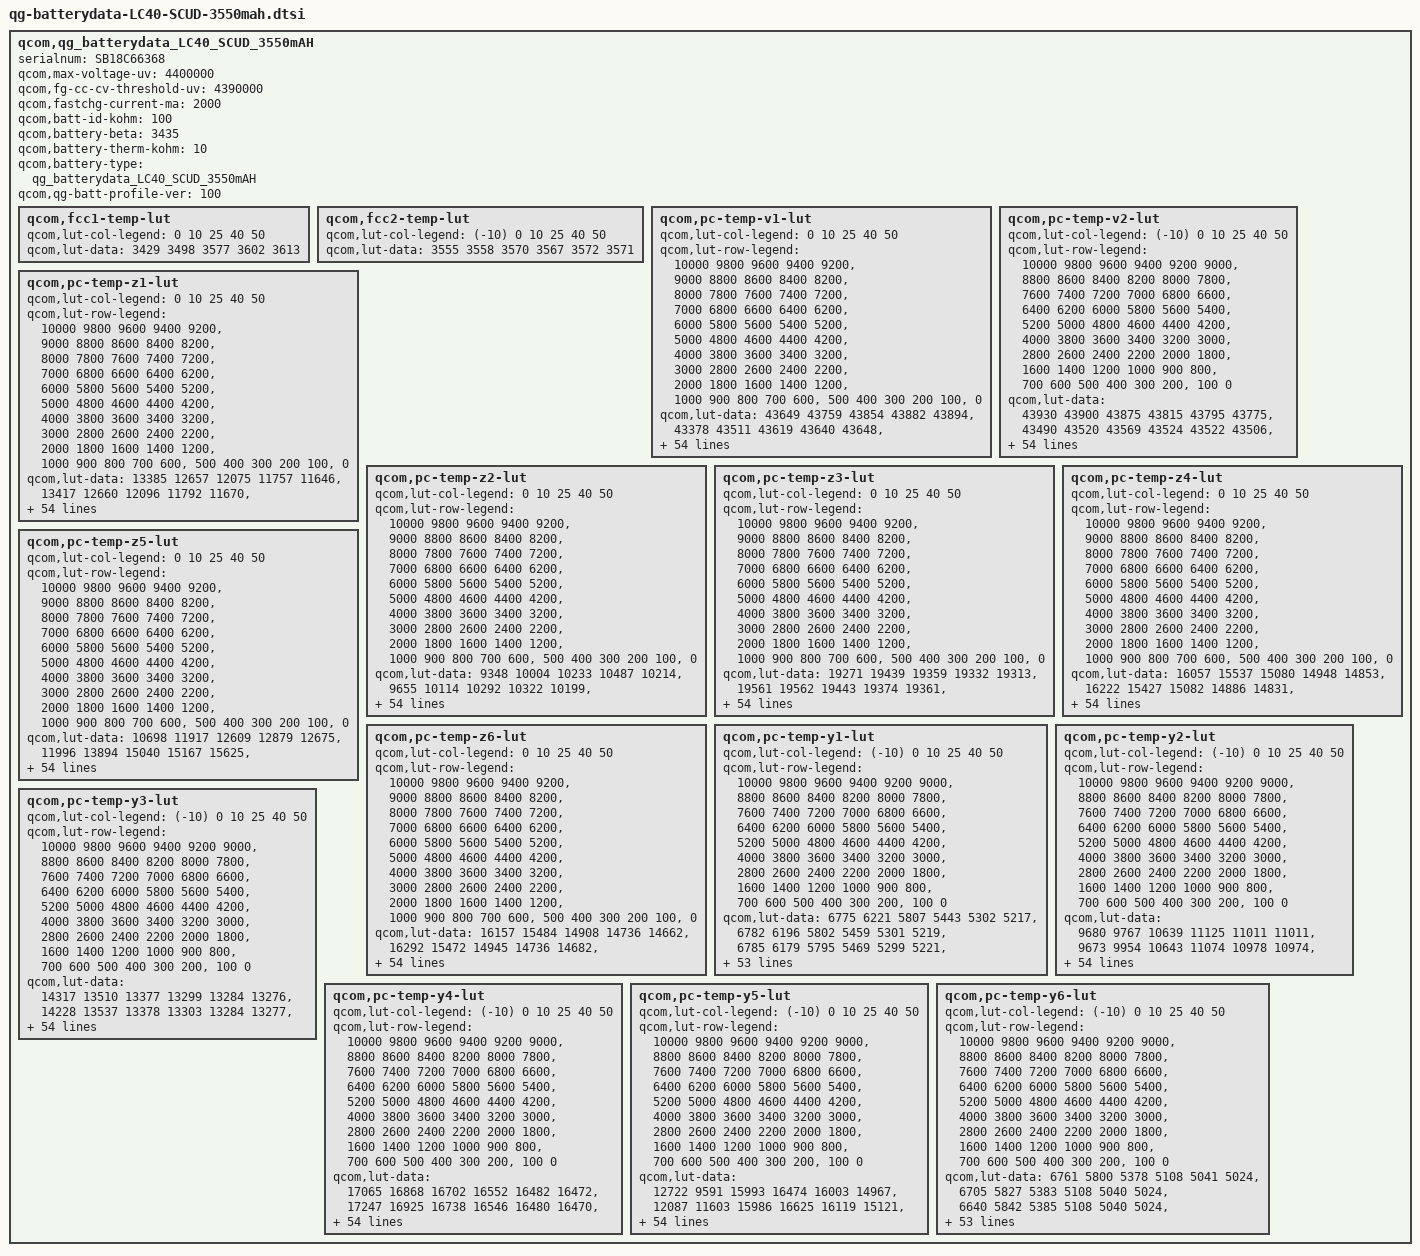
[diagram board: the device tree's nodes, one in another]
/* Copyright (c) 2014-2015, The Linux Foundation. All rights reserved.
 *
 * This program is free software; you can redistribute it and/or modify
 * it under the terms of the GNU General Public License version 2 and
 * only version 2 as published by the Free Software Foundation.
 *
 * This program is distributed in the hope that it will be useful,
 * but WITHOUT ANY WARRANTY; without even the implied warranty of
 * MERCHANTABILITY or FITNESS FOR A PARTICULAR PURPOSE.  See the
 * GNU General Public License for more details.
 */

qcom,qg_batterydata_LC40_SCUD_3550mAH {
        /* qg_batterydata_LC40_SCUD_3550mAH */
        serialnum = "SB18C66368";
        qcom,max-voltage-uv = <4400000>;
        qcom,fg-cc-cv-threshold-uv = <4390000>;
        qcom,fastchg-current-ma = <2000>;
        qcom,batt-id-kohm = <100>;
        qcom,battery-beta = <3435>;
        qcom,battery-therm-kohm = <10>;
        qcom,battery-type = "qg_batterydata_LC40_SCUD_3550mAH";
        qcom,qg-batt-profile-ver = <100>;

	qcom,fcc1-temp-lut {
		qcom,lut-col-legend = <0 10 25 40 50>;
		qcom,lut-data = <3429 3498 3577 3602 3613>;
	};

	qcom,fcc2-temp-lut {
		qcom,lut-col-legend = <(-10) 0 10 25 40 50>;
		qcom,lut-data = <3555 3558 3570 3567 3572 3571>;
	};

	qcom,pc-temp-v1-lut {
		qcom,lut-col-legend = <0 10 25 40 50>;
		qcom,lut-row-legend = <10000 9800 9600 9400 9200>,
			<9000 8800 8600 8400 8200>,
			<8000 7800 7600 7400 7200>,
			<7000 6800 6600 6400 6200>,
			<6000 5800 5600 5400 5200>,
			<5000 4800 4600 4400 4200>,
			<4000 3800 3600 3400 3200>,
			<3000 2800 2600 2400 2200>,
			<2000 1800 1600 1400 1200>,
			<1000 900 800 700 600>,
			<500 400 300 200 100>,
			<0>;
		qcom,lut-data = <43649 43759 43854 43882 43894>,
			<43378 43511 43619 43640 43648>,
			<43098 43258 43385 43411 43422>,
			<42863 43010 43144 43181 43193>,
			<42635 42777 42904 42946 42968>,
			<42408 42545 42665 42710 42735>,
			<42188 42313 42429 42477 42501>,
			<41977 42088 42195 42242 42269>,
			<41774 41874 41966 42011 42038>,
			<41575 41667 41742 41783 41810>,
			<41382 41463 41523 41559 41583>,
			<41191 41263 41310 41338 41361>,
			<41008 41070 41103 41118 41141>,
			<40821 40895 40903 40907 40928>,
			<40575 40708 40713 40710 40723>,
			<40241 40444 40515 40519 40526>,
			<39983 40132 40277 40323 40333>,
			<39847 39940 40041 40128 40148>,
			<39741 39834 39884 39952 39971>,
			<39628 39728 39768 39799 39810>,
			<39516 39594 39623 39633 39641>,
			<39398 39438 39429 39427 39443>,
			<39271 39228 39223 39215 39237>,
			<39134 38953 39008 39023 39043>,
			<38966 38767 38808 38845 38859>,
			<38776 38664 38686 38703 38711>,
			<38636 38587 38601 38590 38595>,
			<38533 38524 38516 38489 38491>,
			<38457 38471 38426 38398 38395>,
			<38406 38419 38343 38315 38307>,
			<38367 38367 38274 38239 38227>,
			<38338 38319 38212 38169 38153>,
			<38315 38274 38161 38107 38088>,
			<38291 38232 38116 38051 38031>,
			<38265 38196 38076 38000 37975>,
			<38237 38162 38041 37953 37920>,
			<38206 38126 38004 37907 37862>,
			<38173 38091 37964 37856 37798>,
			<38127 38046 37916 37797 37725>,
			<38037 37966 37843 37719 37641>,
			<37922 37851 37733 37613 37543>,
			<37814 37724 37610 37493 37428>,
			<37696 37578 37469 37357 37284>,
			<37534 37411 37313 37207 37133>,
			<37371 37259 37160 37059 36992>,
			<37258 37176 37075 36980 36919>,
			<37221 37154 37051 36957 36900>,
			<37193 37130 37035 36943 36883>,
			<37168 37107 37019 36923 36862>,
			<37115 37050 36954 36848 36774>,
			<36860 36795 36693 36569 36470>,
			<36416 36348 36238 36112 36012>,
			<35832 35763 35652 35526 35424>,
			<35036 34964 34850 34724 34618>,
			<33796 33721 33600 33483 33362>,
			<30000 30000 30000 30000 30000>;
	};

	qcom,pc-temp-v2-lut {
		qcom,lut-col-legend = <(-10) 0 10 25 40 50>;
		qcom,lut-row-legend = <10000 9800 9600 9400 9200 9000>,
			<8800 8600 8400 8200 8000 7800>,
			<7600 7400 7200 7000 6800 6600>,
			<6400 6200 6000 5800 5600 5400>,
			<5200 5000 4800 4600 4400 4200>,
			<4000 3800 3600 3400 3200 3000>,
			<2800 2600 2400 2200 2000 1800>,
			<1600 1400 1200 1000 900 800>,
			<700 600 500 400 300 200>,
			<100 0>;
		qcom,lut-data = <43930 43900 43875 43815 43795 43775>,
			<43490 43520 43569 43524 43522 43506>,
			<43097 43183 43283 43251 43261 43248>,
			<42749 42899 43018 42996 43012 43003>,
			<42437 42654 42771 42757 42775 42769>,
			<42200 42405 42528 42520 42540 42535>,
			<42039 42141 42287 42283 42306 42302>,
			<41869 41893 42052 42049 42074 42070>,
			<41558 41681 41829 41823 41846 41841>,
			<41254 41485 41609 41600 41620 41615>,
			<41219 41287 41378 41378 41397 41394>,
			<41228 41091 41141 41158 41178 41177>,
			<41211 40926 40947 40963 40965 40964>,
			<40882 40808 40807 40804 40762 40756>,
			<40422 40660 40650 40629 40560 40553>,
			<40000 40290 40383 40356 40349 40356>,
			<39587 39808 40074 40059 40144 40166>,
			<39340 39579 39860 39887 39968 39987>,
			<39177 39456 39692 39774 39813 39816>,
			<39017 39312 39512 39635 39648 39644>,
			<38844 39110 39308 39444 39475 39475>,
			<38679 38905 39106 39236 39287 39294>,
			<38527 38731 38918 39017 39056 39064>,
			<38390 38570 38743 38800 38823 38830>,
			<38294 38414 38595 38641 38661 38665>,
			<38223 38259 38468 38517 38539 38540>,
			<38164 38155 38352 38407 38429 38428>,
			<38115 38095 38248 38306 38327 38327>,
			<38070 38048 38151 38215 38235 38235>,
			<38025 38007 38050 38132 38150 38148>,
			<37982 37971 37961 38059 38075 38069>,
			<37937 37934 37904 37987 38005 37999>,
			<37891 37896 37864 37920 37943 37936>,
			<37842 37857 37829 37857 37878 37869>,
			<37794 37818 37799 37804 37811 37795>,
			<37743 37777 37766 37751 37738 37712>,
			<37683 37730 37727 37693 37647 37608>,
			<37615 37676 37683 37632 37547 37493>,
			<37543 37611 37626 37563 37461 37398>,
			<37465 37532 37555 37484 37382 37314>,
			<37378 37444 37465 37401 37304 37234>,
			<37285 37343 37347 37303 37212 37144>,
			<37205 37225 37210 37180 37093 37022>,
			<37108 37092 37074 37047 36963 36890>,
			<37025 36965 36945 36904 36837 36781>,
			<36944 36889 36883 36872 36812 36757>,
			<36902 36857 36860 36857 36801 36746>,
			<36854 36826 36833 36841 36781 36729>,
			<36785 36779 36791 36807 36749 36689>,
			<36651 36685 36684 36712 36623 36529>,
			<36398 36444 36405 36408 36277 36145>,
			<35978 35985 35916 35901 35760 35617>,
			<35369 35346 35249 35255 35095 34926>,
			<34488 34438 34315 34373 34169 33967>,
			<33005 33050 32841 32979 32818 32577>,
			<28046 27651 27580 27454 28153 27750>;
	};

	qcom,pc-temp-z1-lut {
		qcom,lut-col-legend = <0 10 25 40 50>;
		qcom,lut-row-legend = <10000 9800 9600 9400 9200>,
			<9000 8800 8600 8400 8200>,
			<8000 7800 7600 7400 7200>,
			<7000 6800 6600 6400 6200>,
			<6000 5800 5600 5400 5200>,
			<5000 4800 4600 4400 4200>,
			<4000 3800 3600 3400 3200>,
			<3000 2800 2600 2400 2200>,
			<2000 1800 1600 1400 1200>,
			<1000 900 800 700 600>,
			<500 400 300 200 100>,
			<0>;
		qcom,lut-data = <13385 12657 12075 11757 11646>,
			<13417 12660 12096 11792 11670>,
			<13416 12663 12101 11787 11675>,
			<13435 12658 12086 11779 11671>,
			<13442 12641 12084 11775 11667>,
			<13433 12633 12073 11767 11664>,
			<13424 12632 12065 11761 11661>,
			<13417 12632 12057 11759 11660>,
			<13405 12625 12053 11757 11659>,
			<13393 12614 12055 11755 11658>,
			<13380 12610 12059 11752 11657>,
			<13366 12608 12060 11752 11657>,
			<13344 12606 12059 11753 11656>,
			<13321 12600 12058 11754 11655>,
			<13311 12592 12050 11749 11655>,
			<13307 12581 12042 11744 11654>,
			<13304 12564 12036 11744 11654>,
			<13298 12561 12032 11745 11655>,
			<13290 12570 12034 11747 11656>,
			<13286 12579 12042 11749 11658>,
			<13284 12585 12049 11751 11659>,
			<13287 12590 12053 11752 11660>,
			<13294 12596 12057 11754 11661>,
			<13303 12606 12062 11755 11662>,
			<13311 12609 12066 11758 11665>,
			<13320 12607 12070 11762 11668>,
			<13324 12605 12073 11767 11672>,
			<13322 12610 12076 11771 11676>,
			<13321 12620 12082 11775 11679>,
			<13335 12624 12088 11779 11681>,
			<13357 12629 12093 11783 11684>,
			<13361 12635 12097 11787 11687>,
			<13348 12641 12101 11791 11690>,
			<13341 12644 12104 11796 11694>,
			<13349 12646 12107 11799 11697>,
			<13363 12651 12113 11801 11699>,
			<13376 12653 12118 11803 11701>,
			<13394 12649 12119 11806 11704>,
			<13407 12648 12120 11810 11708>,
			<13414 12656 12123 11814 11711>,
			<13421 12670 12130 11820 11714>,
			<13439 12683 12135 11824 11718>,
			<13462 12696 12137 11828 11723>,
			<13453 12696 12140 11832 11726>,
			<13443 12692 12145 11837 11726>,
			<13432 12686 12156 11841 11729>,
			<13424 12689 12153 11839 11730>,
			<13419 12691 12159 11839 11731>,
			<13412 12690 12155 11845 11734>,
			<13427 12711 12155 11849 11738>,
			<13462 12707 12162 11857 11746>,
			<13448 12722 12182 11867 11753>,
			<13474 12753 12192 11879 11763>,
			<13529 12787 12224 11901 11780>,
			<13529 12787 12224 11901 11780>,
			<13529 12787 12224 11901 11780>;
	};

	qcom,pc-temp-z2-lut {
		qcom,lut-col-legend = <0 10 25 40 50>;
		qcom,lut-row-legend = <10000 9800 9600 9400 9200>,
			<9000 8800 8600 8400 8200>,
			<8000 7800 7600 7400 7200>,
			<7000 6800 6600 6400 6200>,
			<6000 5800 5600 5400 5200>,
			<5000 4800 4600 4400 4200>,
			<4000 3800 3600 3400 3200>,
			<3000 2800 2600 2400 2200>,
			<2000 1800 1600 1400 1200>,
			<1000 900 800 700 600>,
			<500 400 300 200 100>,
			<0>;
		qcom,lut-data = <9348 10004 10233 10487 10214>,
			<9655 10114 10292 10322 10199>,
			<9948 10112 10305 10193 10166>,
			<9961 10100 10291 10221 10169>,
			<9969 10070 10239 10314 10275>,
			<9974 10046 10224 10277 10232>,
			<9977 10028 10210 10245 10175>,
			<9974 10014 10191 10241 10134>,
			<9965 10000 10180 10238 10098>,
			<9956 9990 10192 10216 10089>,
			<9945 9991 10212 10172 10087>,
			<9936 10005 10217 10163 10090>,
			<9933 10022 10220 10194 10107>,
			<9930 10043 10224 10214 10121>,
			<9920 10058 10234 10189 10126>,
			<9894 10058 10241 10156 10131>,
			<9879 10055 10226 10147 10133>,
			<9882 10057 10205 10142 10137>,
			<9890 10079 10208 10146 10142>,
			<9900 10104 10230 10171 10154>,
			<9917 10128 10259 10212 10171>,
			<9932 10147 10312 10318 10219>,
			<9946 10146 10344 10415 10277>,
			<9958 10135 10290 10377 10296>,
			<9966 10131 10211 10283 10304>,
			<9973 10132 10223 10278 10291>,
			<9980 10134 10293 10361 10250>,
			<9986 10138 10325 10401 10200>,
			<9993 10145 10334 10303 10132>,
			<10002 10147 10337 10200 10075>,
			<10011 10148 10312 10189 10064>,
			<10015 10148 10276 10188 10066>,
			<10016 10150 10275 10196 10075>,
			<10017 10154 10285 10216 10092>,
			<10023 10160 10297 10241 10117>,
			<10033 10172 10315 10284 10162>,
			<10040 10182 10335 10333 10214>,
			<10047 10192 10358 10379 10259>,
			<10054 10201 10383 10421 10298>,
			<10062 10211 10405 10444 10310>,
			<10069 10221 10428 10467 10310>,
			<9962 10223 10437 10470 10311>,
			<9738 10221 10435 10415 10336>,
			<9838 10227 10439 10408 10331>,
			<10020 10266 10458 10449 10269>,
			<10403 10398 10475 10389 10301>,
			<10422 10389 10449 10386 10322>,
			<10436 10396 10437 10423 10334>,
			<10596 10449 10421 10415 10393>,
			<10692 10488 10527 10464 10411>,
			<10482 10491 10593 10381 10236>,
			<9998 10411 10580 10272 10142>,
			<9647 10298 10566 10223 10089>,
			<9534 10106 10497 10180 10036>,
			<9534 10106 10497 10180 10036>,
			<9534 10106 10497 10180 10036>;
	};

	qcom,pc-temp-z3-lut {
		qcom,lut-col-legend = <0 10 25 40 50>;
		qcom,lut-row-legend = <10000 9800 9600 9400 9200>,
			<9000 8800 8600 8400 8200>,
			<8000 7800 7600 7400 7200>,
			<7000 6800 6600 6400 6200>,
			<6000 5800 5600 5400 5200>,
			<5000 4800 4600 4400 4200>,
			<4000 3800 3600 3400 3200>,
			<3000 2800 2600 2400 2200>,
			<2000 1800 1600 1400 1200>,
			<1000 900 800 700 600>,
			<500 400 300 200 100>,
			<0>;
		qcom,lut-data = <19271 19439 19359 19332 19313>,
			<19561 19562 19443 19374 19361>,
			<19862 19624 19446 19381 19367>,
			<19905 19682 19463 19383 19375>,
			<19913 19689 19511 19433 19407>,
			<19907 19694 19515 19437 19412>,
			<19897 19699 19515 19438 19414>,
			<19885 19701 19512 19435 19410>,
			<19872 19697 19506 19429 19402>,
			<19866 19687 19494 19420 19397>,
			<19868 19678 19481 19407 19392>,
			<19869 19668 19477 19402 19388>,
			<19839 19655 19476 19401 19387>,
			<19790 19627 19473 19399 19384>,
			<19793 19605 19460 19390 19378>,
			<19859 19611 19451 19379 19371>,
			<19898 19630 19454 19379 19367>,
			<19875 19631 19459 19381 19366>,
			<19836 19598 19456 19381 19364>,
			<19808 19575 19446 19373 19360>,
			<19785 19581 19444 19369 19358>,
			<19777 19593 19455 19380 19360>,
			<19781 19601 19463 19392 19363>,
			<19790 19610 19453 19381 19362>,
			<19804 19612 19436 19356 19360>,
			<19825 19608 19430 19359 19363>,
			<19831 19603 19427 19409 19395>,
			<19827 19599 19429 19435 19414>,
			<19822 19596 19464 19428 19409>,
			<19816 19596 19490 19418 19401>,
			<19808 19600 19489 19412 19395>,
			<19798 19603 19485 19407 19389>,
			<19784 19604 19480 19403 19383>,
			<19772 19605 19471 19398 19377>,
			<19766 19604 19464 19393 19370>,
			<19761 19601 19457 19386 19362>,
			<19751 19596 19452 19380 19357>,
			<19734 19588 19449 19378 19358>,
			<19721 19579 19446 19377 19362>,
			<19717 19571 19442 19378 19362>,
			<19713 19563 19438 19380 19361>,
			<19570 19557 19433 19380 19360>,
			<19285 19552 19429 19374 19364>,
			<19265 19546 19427 19373 19368>,
			<19263 19532 19424 19377 19370>,
			<19260 19462 19400 19356 19353>,
			<19260 19384 19394 19355 19341>,
			<19260 19363 19389 19347 19338>,
			<19259 19348 19375 19344 19332>,
			<19259 19350 19367 19342 19333>,
			<19260 19347 19354 19358 19357>,
			<19262 19335 19352 19361 19360>,
			<19266 19331 19347 19365 19363>,
			<19269 19326 19346 19374 19370>,
			<19269 19326 19346 19374 19370>,
			<19269 19326 19346 19374 19370>;
	};

	qcom,pc-temp-z4-lut {
		qcom,lut-col-legend = <0 10 25 40 50>;
		qcom,lut-row-legend = <10000 9800 9600 9400 9200>,
			<9000 8800 8600 8400 8200>,
			<8000 7800 7600 7400 7200>,
			<7000 6800 6600 6400 6200>,
			<6000 5800 5600 5400 5200>,
			<5000 4800 4600 4400 4200>,
			<4000 3800 3600 3400 3200>,
			<3000 2800 2600 2400 2200>,
			<2000 1800 1600 1400 1200>,
			<1000 900 800 700 600>,
			<500 400 300 200 100>,
			<0>;
		qcom,lut-data = <16057 15537 15080 14948 14853>,
			<16222 15427 15082 14886 14831>,
			<16451 15370 14957 14825 14790>,
			<16115 15509 14921 14788 14755>,
			<15840 15307 15035 14882 14838>,
			<15662 15158 14957 14847 14814>,
			<15519 15063 14896 14809 14784>,
			<15407 14991 14854 14783 14768>,
			<15315 14936 14824 14764 14756>,
			<15236 14893 14806 14759 14748>,
			<15163 14861 14795 14757 14742>,
			<15108 14837 14788 14752 14736>,
			<15076 14819 14784 14743 14728>,
			<15051 14800 14776 14734 14720>,
			<15018 14789 14758 14728 14715>,
			<14977 14800 14746 14722 14710>,
			<14940 14828 14747 14713 14703>,
			<14911 14832 14747 14704 14696>,
			<14887 14802 14739 14698 14689>,
			<14867 14773 14713 14695 14684>,
			<14850 14759 14706 14694 14682>,
			<14835 14749 14732 14719 14707>,
			<14817 14785 14773 14762 14754>,
			<14805 14918 14850 14818 14794>,
			<14826 14973 14930 14882 14833>,
			<14884 14964 14933 14881 14834>,
			<14916 14950 14910 14808 14780>,
			<14931 14928 14880 14760 14738>,
			<14938 14898 14826 14749 14728>,
			<14930 14872 14786 14741 14721>,
			<14910 14848 14774 14732 14714>,
			<14892 14828 14767 14724 14708>,
			<14876 14813 14765 14719 14703>,
			<14859 14801 14764 14715 14699>,
			<14841 14793 14763 14715 14698>,
			<14824 14787 14764 14720 14703>,
			<14812 14781 14764 14726 14712>,
			<14802 14774 14763 14729 14720>,
			<14794 14770 14762 14731 14726>,
			<14786 14769 14762 14733 14727>,
			<14780 14769 14763 14735 14725>,
			<14918 14767 14762 14735 14723>,
			<15205 14757 14752 14732 14718>,
			<15211 14748 14743 14728 14716>,
			<15150 14734 14733 14722 14714>,
			<15059 14719 14693 14691 14683>,
			<15055 14794 14684 14679 14679>,
			<15049 14811 14674 14664 14659>,
			<15040 14817 14674 14649 14645>,
			<15019 14809 14682 14656 14651>,
			<15028 14824 14719 14666 14660>,
			<15044 14850 14729 14673 14663>,
			<15055 14860 14736 14670 14661>,
			<15077 14877 14743 14662 14654>,
			<15077 14877 14743 14662 14654>,
			<15077 14877 14743 14662 14654>;
	};

	qcom,pc-temp-z5-lut {
		qcom,lut-col-legend = <0 10 25 40 50>;
		qcom,lut-row-legend = <10000 9800 9600 9400 9200>,
			<9000 8800 8600 8400 8200>,
			<8000 7800 7600 7400 7200>,
			<7000 6800 6600 6400 6200>,
			<6000 5800 5600 5400 5200>,
			<5000 4800 4600 4400 4200>,
			<4000 3800 3600 3400 3200>,
			<3000 2800 2600 2400 2200>,
			<2000 1800 1600 1400 1200>,
			<1000 900 800 700 600>,
			<500 400 300 200 100>,
			<0>;
		qcom,lut-data = <10698 11917 12609 12879 12675>,
			<11996 13894 15040 15167 15625>,
			<13150 15017 16054 16443 16726>,
			<13578 14763 17081 17516 19042>,
			<13892 15416 16036 17283 17889>,
			<14122 16161 16672 17696 18409>,
			<14316 17088 17302 18247 19019>,
			<14494 18004 17965 18914 19222>,
			<14669 18679 18393 19476 19283>,
			<14961 19306 18487 19192 19255>,
			<15589 20241 18556 18268 19167>,
			<16006 21593 18811 18073 19271>,
			<15459 22125 19328 18684 19835>,
			<14497 21051 19469 19068 20248>,
			<15063 19898 19144 18475 19953>,
			<19062 20280 18901 17752 19487>,
			<21443 21348 19158 18158 19679>,
			<20460 21541 19805 19435 20662>,
			<19154 20691 21012 20208 21586>,
			<19030 20111 23484 20562 22488>,
			<19217 25000 26396 21159 23037>,
			<19611 32765 30595 24301 23012>,
			<22022 35500 33016 27384 22640>,
			<26040 36889 28898 24067 20578>,
			<32139 37065 22031 16403 16059>,
			<40198 32960 19012 15215 15117>,
			<42377 28183 17147 18040 17500>,
			<40410 26011 16970 19814 19548>,
			<37843 24530 20288 20137 20317>,
			<35842 24418 24084 20428 20946>,
			<33843 25439 26542 21225 21794>,
			<31633 26879 28573 22645 22744>,
			<28906 29087 30033 24420 23690>,
			<27557 31779 31183 26846 24746>,
			<27639 34340 31733 27752 25147>,
			<27757 36880 32019 27373 24517>,
			<27351 37534 32137 26840 23887>,
			<25718 36747 31535 26301 24129>,
			<24971 35527 30246 25600 24633>,
			<26419 33766 28747 24919 24266>,
			<28029 31587 26853 24117 22259>,
			<22779 30123 25650 23131 21443>,
			<11567 29081 24800 21648 22422>,
			<10949 28990 24430 21232 22719>,
			<11021 28696 24181 21405 22156>,
			<11119 20816 24322 20274 20912>,
			<11096 14137 22947 20771 18711>,
			<11078 13047 22623 20779 20337>,
			<11064 12661 19422 22979 22369>,
			<11099 12859 18227 21133 21654>,
			<11186 12776 15235 19603 21846>,
			<11121 12306 14386 18269 20231>,
			<11076 12111 13880 18491 19945>,
			<10995 11850 13475 19445 20496>,
			<10995 11850 13475 19445 20496>,
			<10995 11850 13475 19445 20496>;
	};

	qcom,pc-temp-z6-lut {
		qcom,lut-col-legend = <0 10 25 40 50>;
		qcom,lut-row-legend = <10000 9800 9600 9400 9200>,
			<9000 8800 8600 8400 8200>,
			<8000 7800 7600 7400 7200>,
			<7000 6800 6600 6400 6200>,
			<6000 5800 5600 5400 5200>,
			<5000 4800 4600 4400 4200>,
			<4000 3800 3600 3400 3200>,
			<3000 2800 2600 2400 2200>,
			<2000 1800 1600 1400 1200>,
			<1000 900 800 700 600>,
			<500 400 300 200 100>,
			<0>;
		qcom,lut-data = <16157 15484 14908 14736 14662>,
			<16292 15472 14945 14736 14682>,
			<16478 15448 14889 14712 14668>,
			<16303 15517 14876 14695 14656>,
			<16148 15409 14945 14760 14710>,
			<16033 15326 14909 14747 14702>,
			<15934 15271 14879 14730 14691>,
			<15854 15226 14856 14718 14681>,
			<15787 15188 14838 14706 14672>,
			<15731 15155 14822 14697 14665>,
			<15686 15130 14810 14689 14659>,
			<15642 15109 14806 14683 14654>,
			<15585 15088 14803 14679 14649>,
			<15531 15058 14798 14674 14645>,
			<15513 15037 14779 14666 14639>,
			<15508 15042 14766 14657 14632>,
			<15501 15057 14768 14653 14627>,
			<15477 15058 14770 14650 14623>,
			<15447 15029 14766 14647 14619>,
			<15428 15009 14751 14641 14615>,
			<15412 15010 14747 14639 14613>,
			<15407 15012 14764 14656 14625>,
			<15408 15033 14788 14682 14647>,
			<15409 15097 14818 14700 14665>,
			<15426 15124 14845 14716 14682>,
			<15465 15120 14844 14718 14685>,
			<15483 15113 14833 14714 14679>,
			<15489 15103 14826 14708 14673>,
			<15492 15091 14822 14701 14666>,
			<15488 15082 14819 14693 14659>,
			<15478 15076 14816 14687 14654>,
			<15468 15071 14812 14681 14648>,
			<15455 15067 14808 14676 14643>,
			<15445 15063 14805 14673 14637>,
			<15437 15061 14802 14670 14634>,
			<15431 15059 14800 14669 14633>,
			<15425 15056 14798 14668 14632>,
			<15418 15052 14797 14669 14635>,
			<15416 15049 14796 14670 14640>,
			<15418 15050 14796 14671 14641>,
			<15420 15053 14796 14674 14640>,
			<15415 15053 14796 14674 14640>,
			<15405 15052 14792 14671 14640>,
			<15404 15051 14790 14669 14641>,
			<15393 15047 14787 14670 14642>,
			<15364 15015 14761 14646 14620>,
			<15365 15010 14756 14641 14612>,
			<15361 15008 14749 14630 14602>,
			<15361 15005 14744 14622 14593>,
			<15361 15007 14746 14625 14596>,
			<15376 15021 14758 14640 14615>,
			<15395 15034 14766 14647 14621>,
			<15419 15047 14772 14651 14625>,
			<15461 15070 14783 14657 14629>,
			<15461 15070 14783 14657 14629>,
			<15461 15070 14783 14657 14629>;
	};

	qcom,pc-temp-y1-lut {
		qcom,lut-col-legend = <(-10) 0 10 25 40 50>;
		qcom,lut-row-legend = <10000 9800 9600 9400 9200 9000>,
			<8800 8600 8400 8200 8000 7800>,
			<7600 7400 7200 7000 6800 6600>,
			<6400 6200 6000 5800 5600 5400>,
			<5200 5000 4800 4600 4400 4200>,
			<4000 3800 3600 3400 3200 3000>,
			<2800 2600 2400 2200 2000 1800>,
			<1600 1400 1200 1000 900 800>,
			<700 600 500 400 300 200>,
			<100 0>;
		qcom,lut-data = <6775 6221 5807 5443 5302 5217>,
			<6782 6196 5802 5459 5301 5219>,
			<6785 6179 5795 5469 5299 5221>,
			<6785 6168 5788 5474 5297 5222>,
			<6785 6164 5783 5476 5294 5222>,
			<6788 6166 5781 5476 5291 5222>,
			<6792 6184 5780 5469 5287 5220>,
			<6793 6198 5781 5464 5284 5218>,
			<6781 6189 5779 5462 5283 5217>,
			<6766 6174 5778 5461 5282 5216>,
			<6775 6168 5778 5460 5281 5215>,
			<6797 6165 5779 5459 5278 5213>,
			<6810 6165 5780 5458 5276 5212>,
			<6813 6177 5782 5455 5275 5211>,
			<6813 6188 5784 5454 5274 5211>,
			<6808 6188 5780 5456 5274 5211>,
			<6800 6185 5775 5459 5274 5212>,
			<6800 6190 5779 5460 5273 5212>,
			<6802 6200 5790 5460 5271 5211>,
			<6804 6203 5795 5460 5271 5211>,
			<6802 6191 5794 5460 5273 5210>,
			<6797 6179 5792 5461 5275 5210>,
			<6787 6183 5788 5461 5275 5211>,
			<6771 6190 5784 5463 5274 5213>,
			<6766 6196 5785 5466 5275 5214>,
			<6755 6202 5794 5471 5278 5215>,
			<6756 6203 5798 5474 5280 5216>,
			<6782 6190 5800 5476 5283 5216>,
			<6804 6178 5801 5479 5285 5217>,
			<6791 6184 5797 5483 5287 5219>,
			<6762 6196 5790 5489 5289 5222>,
			<6756 6200 5789 5491 5292 5225>,
			<6763 6203 5789 5494 5296 5228>,
			<6766 6202 5789 5496 5299 5231>,
			<6752 6191 5792 5494 5303 5232>,
			<6737 6182 5795 5494 5305 5234>,
			<6737 6189 5795 5496 5307 5235>,
			<6738 6205 5795 5500 5309 5237>,
			<6742 6205 5796 5503 5312 5240>,
			<6754 6187 5798 5506 5315 5244>,
			<6756 6182 5802 5517 5319 5245>,
			<6753 6184 5812 5523 5322 5247>,
			<6768 6213 5806 5524 5328 5249>,
			<6812 6209 5808 5523 5329 5252>,
			<6796 6223 5813 5533 5335 5257>,
			<6817 6222 5825 5540 5340 5262>,
			<6800 6231 5825 5537 5339 5261>,
			<6836 6237 5820 5546 5341 5260>,
			<6810 6234 5827 5555 5339 5260>,
			<6803 6234 5829 5545 5339 5262>,
			<6877 6247 5832 5549 5344 5265>,
			<6867 6241 5851 5555 5353 5270>,
			<6853 6285 5858 5568 5365 5278>,
			<6920 6326 5881 5584 5377 5289>,
			<6920 6326 5881 5584 5377 5289>,
			<6920 6326 5881 5584 5377 5289>;
	};

	qcom,pc-temp-y2-lut {
		qcom,lut-col-legend = <(-10) 0 10 25 40 50>;
		qcom,lut-row-legend = <10000 9800 9600 9400 9200 9000>,
			<8800 8600 8400 8200 8000 7800>,
			<7600 7400 7200 7000 6800 6600>,
			<6400 6200 6000 5800 5600 5400>,
			<5200 5000 4800 4600 4400 4200>,
			<4000 3800 3600 3400 3200 3000>,
			<2800 2600 2400 2200 2000 1800>,
			<1600 1400 1200 1000 900 800>,
			<700 600 500 400 300 200>,
			<100 0>;
		qcom,lut-data = <9680 9767 10639 11125 11011 11011>,
			<9673 9954 10643 11074 10978 10974>,
			<9669 10091 10645 11025 10935 10917>,
			<9670 10181 10645 10979 10891 10858>,
			<9674 10228 10644 10940 10857 10813>,
			<9697 10231 10641 10908 10842 10798>,
			<9891 10164 10626 10881 10834 10795>,
			<10039 10112 10614 10860 10828 10793>,
			<9907 10164 10615 10838 10827 10781>,
			<9699 10258 10618 10821 10829 10765>,
			<9671 10315 10599 10817 10817 10759>,
			<9672 10383 10542 10818 10790 10757>,
			<9674 10408 10538 10813 10781 10750>,
			<9675 10399 10718 10785 10784 10729>,
			<9676 10401 10854 10764 10789 10715>,
			<9673 10447 10835 10822 10817 10725>,
			<9667 10522 10804 10933 10867 10748>,
			<9665 10593 10817 11003 10910 10775>,
			<9664 10666 10876 11058 10958 10816>,
			<9664 10711 10895 11095 11019 10879>,
			<9664 10739 10876 11125 11124 11031>,
			<9664 10753 10860 11140 11188 11132>,
			<9663 10702 10870 11106 11104 11081>,
			<9663 10561 10888 11052 10978 11000>,
			<9663 10326 10897 11050 10984 10979>,
			<9662 9894 10908 11073 11058 10971>,
			<9662 9706 10922 11085 11093 10971>,
			<9661 9697 10946 11096 11096 11003>,
			<9660 9692 10962 11113 11102 11048>,
			<9660 9686 10961 11150 11128 11103>,
			<9660 9680 10959 11194 11161 11159>,
			<9659 9676 10954 11205 11182 11174>,
			<9659 9672 10941 11208 11202 11181>,
			<9659 9669 10921 11208 11211 11181>,
			<9658 9666 10873 11201 11241 11156>,
			<9658 9664 10820 11190 11260 11127>,
			<9658 9662 10786 11167 11211 11110>,
			<9658 9661 10754 11131 11137 11096>,
			<9658 9659 10711 11106 11111 11084>,
			<9657 9658 10655 11086 11101 11052>,
			<9657 9658 10594 11036 11104 11067>,
			<9657 9657 10335 10982 11113 11070>,
			<9657 9657 9940 11007 11105 10985>,
			<9657 9657 9806 10983 11102 11090>,
			<9657 9656 9716 10881 11046 10968>,
			<9657 9656 9691 10869 11018 10869>,
			<9656 9656 9685 10821 10934 10824>,
			<9656 9656 9679 10828 10941 10802>,
			<9656 9655 9677 10820 10958 10864>,
			<9656 9655 9673 10800 10932 10830>,
			<9656 9655 9671 10748 10912 10752>,
			<9656 9655 9667 10695 10871 10713>,
			<9655 9654 9663 10627 10783 10642>,
			<9654 9654 9659 10587 10698 10499>,
			<9654 9654 9659 10587 10698 10499>,
			<9654 9654 9659 10587 10698 10499>;
	};

	qcom,pc-temp-y3-lut {
		qcom,lut-col-legend = <(-10) 0 10 25 40 50>;
		qcom,lut-row-legend = <10000 9800 9600 9400 9200 9000>,
			<8800 8600 8400 8200 8000 7800>,
			<7600 7400 7200 7000 6800 6600>,
			<6400 6200 6000 5800 5600 5400>,
			<5200 5000 4800 4600 4400 4200>,
			<4000 3800 3600 3400 3200 3000>,
			<2800 2600 2400 2200 2000 1800>,
			<1600 1400 1200 1000 900 800>,
			<700 600 500 400 300 200>,
			<100 0>;
		qcom,lut-data = <14317 13510 13377 13299 13284 13276>,
			<14228 13537 13378 13303 13284 13277>,
			<14141 13552 13380 13305 13285 13278>,
			<14061 13559 13381 13308 13285 13279>,
			<13992 13561 13383 13309 13286 13280>,
			<13941 13560 13385 13309 13287 13281>,
			<13908 13547 13387 13308 13288 13282>,
			<13870 13537 13389 13307 13289 13282>,
			<13782 13579 13391 13307 13290 13283>,
			<13686 13643 13393 13308 13291 13283>,
			<13665 13606 13393 13310 13292 13285>,
			<13659 13447 13391 13314 13293 13288>,
			<13659 13388 13389 13318 13294 13290>,
			<13685 13425 13378 13325 13294 13291>,
			<13707 13455 13370 13330 13295 13291>,
			<13665 13452 13368 13324 13297 13291>,
			<13592 13444 13367 13315 13299 13290>,
			<13576 13438 13367 13314 13300 13291>,
			<13573 13434 13366 13315 13300 13292>,
			<13573 13427 13365 13315 13300 13293>,
			<13582 13413 13358 13314 13299 13295>,
			<13590 13398 13350 13312 13298 13295>,
			<13585 13390 13345 13307 13292 13290>,
			<13574 13382 13341 13301 13285 13283>,
			<13574 13362 13339 13299 13284 13280>,
			<13587 13318 13337 13298 13284 13279>,
			<13606 13300 13335 13298 13284 13279>,
			<13638 13307 13332 13297 13283 13279>,
			<13677 13321 13329 13297 13282 13280>,
			<13712 13338 13324 13298 13282 13279>,
			<13749 13363 13318 13299 13282 13278>,
			<13790 13389 13318 13299 13283 13278>,
			<13836 13415 13320 13298 13283 13279>,
			<13884 13446 13323 13298 13283 13280>,
			<13937 13485 13327 13298 13284 13280>,
			<13992 13529 13331 13298 13284 13280>,
			<14046 13582 13336 13297 13283 13279>,
			<14100 13642 13339 13297 13282 13278>,
			<14151 13704 13343 13297 13282 13278>,
			<14199 13767 13347 13298 13282 13279>,
			<14242 13829 13349 13298 13283 13280>,
			<14279 13884 13350 13298 13283 13281>,
			<14269 13870 13339 13299 13283 13279>,
			<14264 13894 13353 13299 13282 13279>,
			<14378 14003 13373 13297 13280 13278>,
			<14466 14117 13398 13303 13285 13282>,
			<14518 14172 13413 13306 13288 13287>,
			<14573 14225 13429 13312 13291 13290>,
			<14635 14277 13455 13317 13297 13292>,
			<14687 14318 13469 13323 13295 13290>,
			<14752 14357 13488 13321 13292 13288>,
			<14829 14432 13532 13322 13293 13289>,
			<14950 14548 13605 13331 13299 13293>,
			<15164 14669 13722 13343 13304 13298>,
			<15164 14669 13722 13343 13304 13298>,
			<15164 14669 13722 13343 13304 13298>;
	};

	qcom,pc-temp-y4-lut {
		qcom,lut-col-legend = <(-10) 0 10 25 40 50>;
		qcom,lut-row-legend = <10000 9800 9600 9400 9200 9000>,
			<8800 8600 8400 8200 8000 7800>,
			<7600 7400 7200 7000 6800 6600>,
			<6400 6200 6000 5800 5600 5400>,
			<5200 5000 4800 4600 4400 4200>,
			<4000 3800 3600 3400 3200 3000>,
			<2800 2600 2400 2200 2000 1800>,
			<1600 1400 1200 1000 900 800>,
			<700 600 500 400 300 200>,
			<100 0>;
		qcom,lut-data = <17065 16868 16702 16552 16482 16472>,
			<17247 16925 16738 16546 16480 16470>,
			<17367 16989 16772 16542 16477 16467>,
			<17437 17049 16800 16538 16475 16466>,
			<17469 17098 16818 16536 16473 16465>,
			<17468 17125 16820 16536 16473 16464>,
			<17400 17144 16809 16537 16473 16464>,
			<17347 17152 16801 16539 16474 16464>,
			<17471 17086 16804 16543 16475 16467>,
			<17733 16983 16809 16549 16477 16470>,
			<17978 17089 16805 16552 16480 16471>,
			<18241 17508 16789 16555 16485 16471>,
			<18305 17675 16800 16561 16491 16472>,
			<17964 17662 16988 16591 16499 16477>,
			<17554 17628 17132 16613 16508 16484>,
			<17290 17355 17047 16612 16513 16492>,
			<17089 16943 16910 16611 16518 16501>,
			<17049 16897 16875 16630 16531 16512>,
			<17042 16954 16863 16696 16554 16525>,
			<17027 16975 16843 16719 16577 16541>,
			<16955 16916 16797 16700 16601 16565>,
			<16881 16837 16742 16667 16614 16579>,
			<16850 16775 16687 16605 16568 16541>,
			<16830 16724 16638 16534 16495 16482>,
			<16829 16719 16613 16515 16479 16470>,
			<16839 16730 16599 16509 16473 16468>,
			<16844 16735 16587 16508 16473 16468>,
			<16837 16734 16577 16510 16478 16471>,
			<16830 16731 16566 16514 16486 16476>,
			<16830 16727 16546 16520 16495 16484>,
			<16831 16721 16526 16526 16504 16494>,
			<16834 16720 16524 16529 16516 16505>,
			<16846 16724 16528 16531 16531 16518>,
			<16855 16730 16535 16532 16535 16522>,
			<16861 16740 16547 16530 16533 16522>,
			<16864 16752 16562 16527 16529 16522>,
			<16867 16765 16580 16522 16508 16506>,
			<16869 16778 16599 16514 16478 16478>,
			<16869 16781 16615 16506 16472 16469>,
			<16860 16781 16628 16499 16470 16466>,
			<16855 16779 16629 16507 16477 16472>,
			<16848 16770 16636 16517 16481 16476>,
			<16818 16738 16631 16503 16469 16465>,
			<16814 16717 16634 16505 16470 16461>,
			<16812 16714 16646 16502 16453 16444>,
			<16836 16726 16670 16522 16471 16465>,
			<16860 16745 16692 16540 16485 16482>,
			<16885 16774 16726 16558 16508 16515>,
			<16919 16821 16766 16583 16540 16548>,
			<16941 16872 16816 16596 16530 16516>,
			<16941 16879 16802 16575 16483 16469>,
			<16925 16835 16782 16571 16481 16469>,
			<16930 16830 16795 16598 16495 16478>,
			<16995 16843 16839 16650 16544 16537>,
			<16995 16843 16839 16650 16544 16537>,
			<16995 16843 16839 16650 16544 16537>;
	};

	qcom,pc-temp-y5-lut {
		qcom,lut-col-legend = <(-10) 0 10 25 40 50>;
		qcom,lut-row-legend = <10000 9800 9600 9400 9200 9000>,
			<8800 8600 8400 8200 8000 7800>,
			<7600 7400 7200 7000 6800 6600>,
			<6400 6200 6000 5800 5600 5400>,
			<5200 5000 4800 4600 4400 4200>,
			<4000 3800 3600 3400 3200 3000>,
			<2800 2600 2400 2200 2000 1800>,
			<1600 1400 1200 1000 900 800>,
			<700 600 500 400 300 200>,
			<100 0>;
		qcom,lut-data = <12722 9591 15993 16474 16003 14967>,
			<12087 11603 15986 16625 16119 15121>,
			<11821 13294 16007 16712 16170 15226>,
			<11860 14565 16041 16754 16178 15295>,
			<12142 15314 16074 16766 16169 15343>,
			<12819 15414 16101 16690 16162 15379>,
			<15855 14739 16172 15837 16124 15350>,
			<18085 14221 16219 14975 16074 15256>,
			<15603 16614 16082 14545 15965 14935>,
			<11702 20289 15745 14266 15773 14564>,
			<11637 19184 15041 14313 15532 14857>,
			<13715 13673 13724 14557 15169 15918>,
			<16218 11807 13061 14614 14757 16254>,
			<19891 15480 12812 14229 14191 15814>,
			<22287 18521 12711 13863 13870 15236>,
			<18948 17840 14369 13724 14097 14636>,
			<13139 16657 17108 13625 14432 14105>,
			<12313 16826 18037 13643 14369 13959>,
			<12825 18240 18462 13798 14041 13894>,
			<13251 19010 18854 14229 14058 13981>,
			<13600 19179 19268 16730 15584 15231>,
			<13815 19292 19592 18731 16804 16505>,
			<13241 19555 19810 18800 16837 17099>,
			<12054 19901 19967 18793 16824 17486>,
			<11578 18788 20075 18753 17088 17315>,
			<11359 13643 20227 18608 17806 16568>,
			<11296 11270 20339 18538 17961 16153>,
			<11452 11279 20485 18370 16749 16024>,
			<11675 11301 20579 18254 15803 15848>,
			<11837 11438 19061 18757 15811 15257>,
			<11980 11722 16573 19647 15846 14570>,
			<12066 11916 16178 20027 15949 14584>,
			<12113 12049 16469 20232 16266 15024>,
			<12185 12207 16701 20386 16791 15558>,
			<12426 12441 17200 20578 18175 16293>,
			<12678 12694 17663 20686 19136 17037>,
			<12763 12942 17678 20278 19000 17719>,
			<12811 13166 17514 19457 18688 18255>,
			<12820 13180 17416 18954 18374 18220>,
			<12810 13039 17143 18466 17985 17900>,
			<12567 12998 16769 17244 17339 17709>,
			<12217 12901 15322 16236 17023 17733>,
			<12335 12700 13078 17082 17735 16893>,
			<11816 12431 12944 16936 17468 18026>,
			<12098 12364 12754 15621 16716 17669>,
			<12100 12640 12955 15606 15877 15580>,
			<12112 12635 12939 15102 15534 16219>,
			<12361 12737 12841 15178 15226 15739>,
			<12711 12863 13059 14834 16039 15391>,
			<12949 13004 13058 15697 16083 15769>,
			<13068 12986 12987 15806 17292 17343>,
			<12868 12857 12994 16052 17936 17982>,
			<12631 12724 12822 16734 20211 18909>,
			<12409 12896 12890 18206 21219 21876>,
			<12409 12896 12890 18206 21219 21876>,
			<12409 12896 12890 18206 21219 21876>;
	};

	qcom,pc-temp-y6-lut {
		qcom,lut-col-legend = <(-10) 0 10 25 40 50>;
		qcom,lut-row-legend = <10000 9800 9600 9400 9200 9000>,
			<8800 8600 8400 8200 8000 7800>,
			<7600 7400 7200 7000 6800 6600>,
			<6400 6200 6000 5800 5600 5400>,
			<5200 5000 4800 4600 4400 4200>,
			<4000 3800 3600 3400 3200 3000>,
			<2800 2600 2400 2200 2000 1800>,
			<1600 1400 1200 1000 900 800>,
			<700 600 500 400 300 200>,
			<100 0>;
		qcom,lut-data = <6761 5800 5378 5108 5041 5024>,
			<6705 5827 5383 5108 5040 5024>,
			<6640 5842 5385 5108 5040 5024>,
			<6577 5850 5384 5108 5040 5025>,
			<6528 5852 5383 5107 5040 5025>,
			<6503 5851 5380 5107 5040 5025>,
			<6493 5832 5371 5105 5040 5026>,
			<6481 5818 5364 5105 5041 5026>,
			<6436 5817 5362 5105 5042 5027>,
			<6383 5817 5360 5106 5043 5029>,
			<6396 5818 5355 5108 5045 5030>,
			<6469 5821 5345 5110 5047 5032>,
			<6494 5827 5345 5115 5049 5034>,
			<6420 5846 5385 5127 5051 5036>,
			<6318 5861 5415 5136 5054 5038>,
			<6216 5790 5390 5132 5057 5040>,
			<6123 5673 5350 5126 5060 5043>,
			<6108 5659 5340 5131 5065 5046>,
			<6107 5674 5337 5150 5071 5050>,
			<6105 5679 5332 5157 5077 5056>,
			<6094 5657 5312 5150 5083 5063>,
			<6081 5630 5291 5139 5086 5067>,
			<6073 5614 5272 5118 5068 5053>,
			<6068 5602 5256 5094 5042 5030>,
			<6070 5591 5250 5088 5037 5025>,
			<6086 5580 5246 5086 5036 5023>,
			<6106 5577 5244 5086 5036 5023>,
			<6130 5592 5242 5087 5036 5025>,
			<6158 5617 5239 5089 5038 5027>,
			<6185 5641 5235 5092 5040 5029>,
			<6214 5670 5230 5095 5044 5031>,
			<6248 5701 5232 5098 5048 5034>,
			<6286 5737 5241 5099 5053 5039>,
			<6326 5777 5252 5100 5054 5041>,
			<6368 5824 5267 5101 5054 5041>,
			<6411 5877 5285 5101 5054 5041>,
			<6454 5935 5306 5101 5048 5036>,
			<6497 5996 5331 5100 5038 5027>,
			<6536 6055 5357 5100 5037 5026>,
			<6573 6110 5387 5101 5037 5026>,
			<6605 6163 5418 5105 5040 5028>,
			<6632 6206 5444 5112 5042 5030>,
			<6624 6190 5428 5110 5039 5026>,
			<6626 6204 5459 5113 5039 5025>,
			<6709 6289 5508 5116 5033 5020>,
			<6793 6380 5569 5132 5044 5030>,
			<6838 6431 5605 5142 5050 5038>,
			<6889 6483 5644 5155 5058 5050>,
			<6947 6537 5688 5168 5072 5061>,
			<6996 6584 5728 5178 5068 5050>,
			<7054 6621 5752 5174 5053 5036>,
			<7121 6671 5804 5181 5054 5038>,
			<7227 6765 5902 5207 5064 5044>,
			<7435 6873 6029 5243 5084 5066>,
			<7435 6873 6029 5243 5084 5066>,
			<7435 6873 6029 5243 5084 5066>;
	};

};
